# STM32L010x4 register map
File version: 1.0
Registers are 32-bit, read-write, reset 0x0 unless marked. A register's access mark holds for its fields unless they carry their own. Offsets are from the block's base; [hi:lo] are bit positions; {n}, {i} and the like mark numbered series; 'fields as' and 'values as' point back to an identical list.

## DBGMCU — Debug MCU
Base 0x40015800
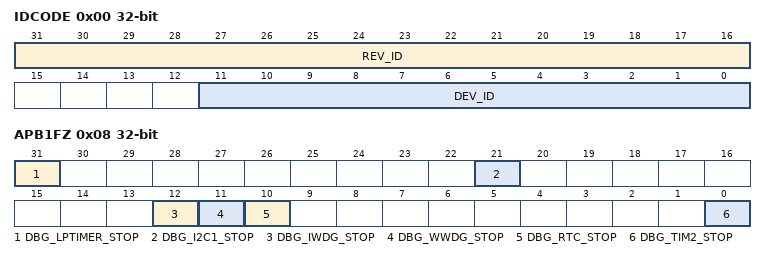
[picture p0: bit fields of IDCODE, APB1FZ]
0x00 IDCODE — MCU device ID code
  [31:16] REV_ID — REV_ID[15:0] bits (Revision Identifier)
  [11:0] DEV_ID — Device Identifier
0x04 CR — Debug MCU configuration register
  [2:0] DBG — Debug mode mask
0x08 APB1FZ — Debug MCU APB1 freeze register
  [31] DBG_LPTIMER_STOP — LPTIM1 counter stopped when core is halted
  [21] DBG_I2C1_STOP — I2C1 SMBUS timeout mode stopped when Core is halted
  [12] DBG_IWDG_STOP — Debug Independent Watchdog stopped when Core is halted
  [11] DBG_WWDG_STOP — Debug Window Watchdog stopped when Core is halted
  [10] DBG_RTC_STOP — RTC Calendar frozen when core is halted
  [0] DBG_TIM2_STOP — TIM2 counter stopped when core is halted
0x0C APB2FZ — Debug MCU APB2 freeze register
  [2] DBG_TIM21_STOP — TIM21 counter stopped when core is halted

## DMA1
Base 0x40020000
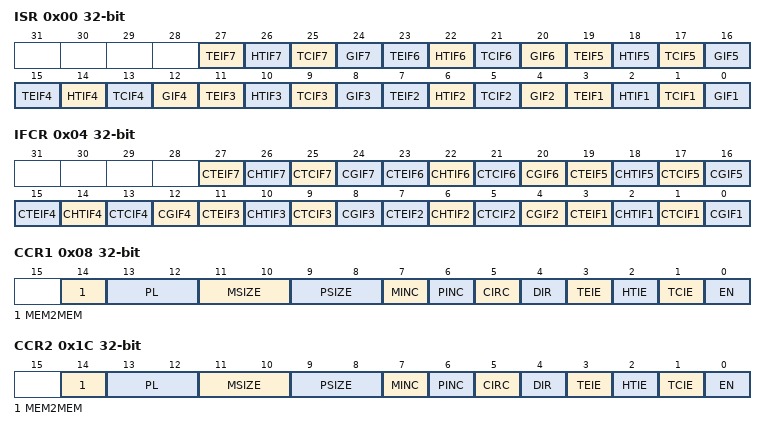
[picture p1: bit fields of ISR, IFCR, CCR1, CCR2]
0x00 ISR — DMA interrupt status register
  [4n-1] TEIF{n} (n=1..7) — Channel {n} Transfer Error flag
  [4n-2] HTIF{n} (n=1..7) — Channel {n} Half Transfer flag
  [4n-3] TCIF{n} (n=1..7) — Channel {n} Transfer Complete flag
  [4n-4] GIF{n} (n=1..7) — Channel {n} Global interrupt flag
0x04 IFCR — DMA interrupt flag clear register
  [4n-1] CTEIF{n} (n=1..7) — Channel {n} Transfer Error clear
  [4n-2] CHTIF{n} (n=1..7) — Channel {n} Half Transfer clear
  [4n-3] CTCIF{n} (n=1..7) — Channel {n} Transfer Complete clear
  [4n-4] CGIF{n} (n=1..7) — Channel {n} Global interrupt clear
0x08 CCR1 — DMA channel x configuration register
  [14] MEM2MEM — Memory to memory mode
  [13:12] PL — PL[1:0] bits(Channel Priority level)
  [11:10] MSIZE — MSIZE[1:0] bits (Memory size)
  [9:8] PSIZE — PSIZE[1:0] bits (Peripheral size)
  [7] MINC — Memory increment mode
  [6] PINC — Peripheral increment mode
  [5] CIRC — Circular mode
  [4] DIR — Data transfer direction
  [3] TEIE — Transfer error interrupt enable
  [2] HTIE — Half Transfer interrupt enable
  [1] TCIE — Transfer complete interrupt enable
  [0] EN — Channel enable
0x0C CNDTR1 — DMA channel x number of data register
  [15:0] NDT — Number of data to Transfer
0x10 CPAR1 — DMA channel x peripheral address register
  [31:0] PA — Peripheral Address
{0x0+0x14*i} CMAR{i} (i=1..5) — DMA channel x memory address register
  [31:0] MA — Memory Address
0x1C CCR2 — DMA channel x configuration register
  fields as CCR1
0x20 CNDTR2 — DMA channel x number of data register
  [15:0] NDT — Number of data to Transfer
0x24 CPAR2 — DMA channel x peripheral address register
  [31:0] PA — Peripheral Address
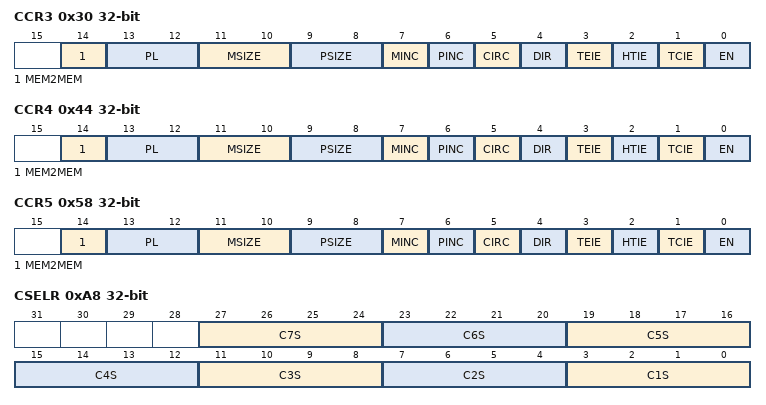
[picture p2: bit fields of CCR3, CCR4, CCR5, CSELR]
0x30 CCR3 — DMA channel x configuration register
  fields as CCR1
0x34 CNDTR3 — DMA channel x number of data register
  [15:0] NDT — Number of data to Transfer
0x38 CPAR3 — DMA channel x peripheral address register
  [31:0] PA — Peripheral Address
0x44 CCR4 — DMA channel x configuration register
  fields as CCR1
0x48 CNDTR4 — DMA channel x number of data register
  [15:0] NDT — Number of data to Transfer
0x4C CPAR4 — DMA channel x peripheral address register
  [31:0] PA — Peripheral Address
0x58 CCR5 — DMA channel x configuration register
  fields as CCR1
0x5C CNDTR5 — DMA channel x number of data register
  [15:0] NDT — Number of data to Transfer
0x60 CPAR5 — DMA channel x peripheral address register
  [31:0] PA — Peripheral Address
0xA8 CSELR — DMA channel selection register
  [4n-1:4n-4] C{n}S (n=1..7) — Channel {n} Selection

## FLASH — FLASH Registers
Base 0x40022000
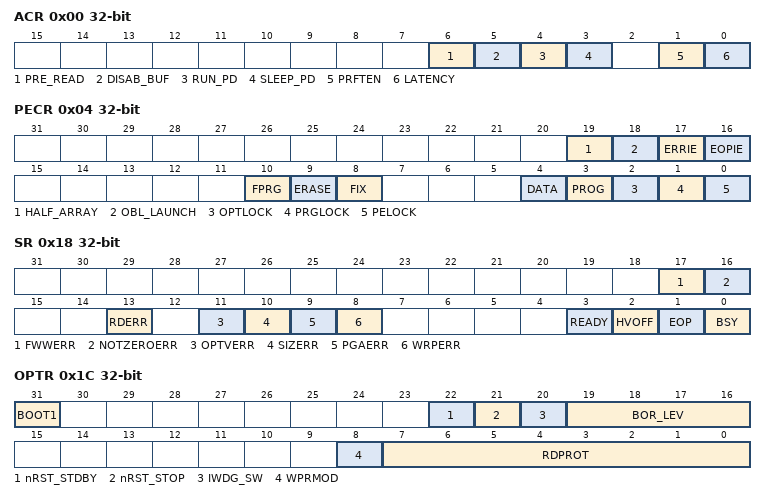
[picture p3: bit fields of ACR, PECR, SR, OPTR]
0x00 ACR — Access control register
  [6] PRE_READ — Pre-read data address
  [5] DISAB_BUF — Disable Buffer
  [4] RUN_PD — Flash mode during RUN mode
  [3] SLEEP_PD — Flash mode during sleep mode
  [1] PRFTEN — Prefetch Buffer Enable
  [0] LATENCY — LATENCY bit (Latency)
    0=FLASH Zero Latency cycle; 1=FLASH One Latency cycle
0x04 PECR — Program/erase control register
  [19] HALF_ARRAY — Half array mode
  [18] OBL_LAUNCH — Launch the option byte loading
  [17] ERRIE — Error interrupt
  [16] EOPIE — End of programming interrupt
  [10] FPRG — Fast Page/Half Page programming mode
  [9] ERASE — Page erasing mode
  [8] FIX — Fixed Time Data write for Word/Half Word/Byte programming
  [4] DATA — Data matrix selection
  [3] PROG — Program matrix selection
  [2] OPTLOCK — Option byte matrix Lock
  [1] PRGLOCK — Program matrix Lock
  [0] PELOCK — FLASH_PECR and Flash data Lock
0x08 PDKEYR — Power down key register
  [31:0] PDKEYR — FLASH_PEC and data matrix Key
0x0C PEKEYR — Program/erase key register
  [31:0] PEKEYR — FLASH_PEC and data matrix Key
0x10 PRGKEYR — Program memory key register
  [31:0] PRGKEYR — Program matrix Key
0x14 OPTKEYR — Option byte key register
  [31:0] OPTKEYR — Option bytes matrix Key
0x18 SR — Status register
  [17] FWWERR — Write/Errase operation aborted
  [16] NOTZEROERR — Not Zero error
  [13] RDERR — Read protected error
  [11] OPTVERR — Option Valid error
  [10] SIZERR — Size error
  [9] PGAERR — Programming Alignment Error
  [8] WRPERR — Write protection error
  [3] READY — Flash ready after low power mode
  [2] HVOFF — End of high voltage
  [1] EOP — End Of Programming
  [0] BSY — Busy
0x1C OPTR — Option byte register
  [31] BOOT1
  [22] nRST_STDBY
  [21] nRST_STOP
  [20] IWDG_SW
  [19:16] BOR_LEV — BOR_LEV[3:0] Brown Out Reset Threshold Level
  [8] WPRMOD — Selection of protection mode of WPR bits
  [7:0] RDPROT — Read Protection
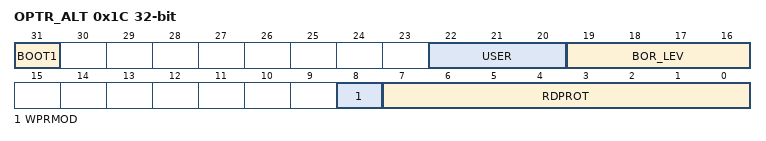
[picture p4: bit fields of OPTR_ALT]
0x1C OPTR_ALT (alternate view of OPTR) — Option byte register
  [31] BOOT1
  [22:20] USER — User Option Bytes
  [19:16] BOR_LEV — BOR_LEV[3:0] Brown Out Reset Threshold Level
  [8] WPRMOD — Selection of protection mode of WPR bits
  [7:0] RDPROT — Read Protection
0x20 WRPR — Write protection register
  [15:0] WRP — Write Protection bits

## CRC — CRC calculation unit
Base 0x40023000
0x00 DR — CRC Data register
  [31:0] DR — Data register bits
0x04 IDR 8-bit — CRC Independent data register
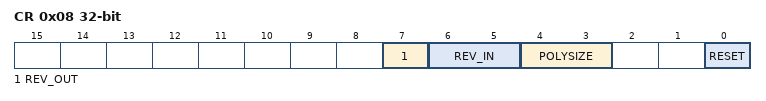
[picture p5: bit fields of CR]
0x08 CR — CRC Control register
  [7] REV_OUT — REV_OUT Reverse Output Data bits
    0=NONE (Output Data bit order not affected); 1=BIT (Output Data bit reversal done by bit)
  [6:5] REV_IN — REV_IN Reverse Input Data bits
    0=NONE (Input Data bit order not affected); 1=BYTE (Input Data bit reversal done by byte); 2=HALFWORD (Input Data bit reversal done by half-word); 3=WORD (Input Data bit reversal done by word)
  [4:3] POLYSIZE — Polynomial size bits
    0=POLYLENGTH_32B (32 bits Polynomial size); 1=POLYLENGTH_16B (16 bits Polynomial size); 2=POLYLENGTH_8B (8 bits Polynomial size); 3=POLYLENGTH_7B (7 bits Polynomial size)
  [0] RESET — RESET the CRC computation unit bit
0x10 INIT — Initial CRC value register
  [31:0] INIT — Initial CRC value bits
0x14 POL — CRC polynomial register
  [31:0] POL — Coefficients of the polynomial

## GPIOA — General Purpose IO
Base 0x50000000
Same registers: GPIOB 0x50000400, GPIOC 0x50000800
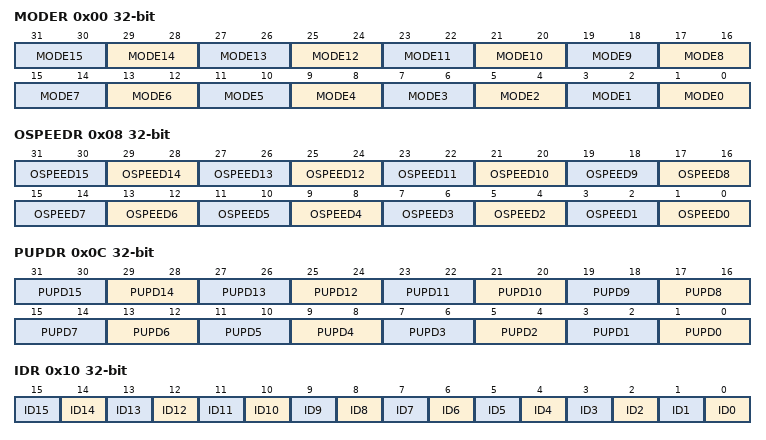
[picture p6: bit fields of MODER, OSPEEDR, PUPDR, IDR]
0x00 MODER — GPIO port mode register
  [2n+1:2n] MODE{n} (n=0..15)
0x04 OTYPER — GPIO port output type register
0x08 OSPEEDR — GPIO port output speed register
  [2n+1:2n] OSPEED{n} (n=0..15)
0x0C PUPDR — GPIO port pull-up/pull-down register
  [2n+1:2n] PUPD{n} (n=0..15)
0x10 IDR — GPIO port input data register
  [n] ID{n} (n=0..15)
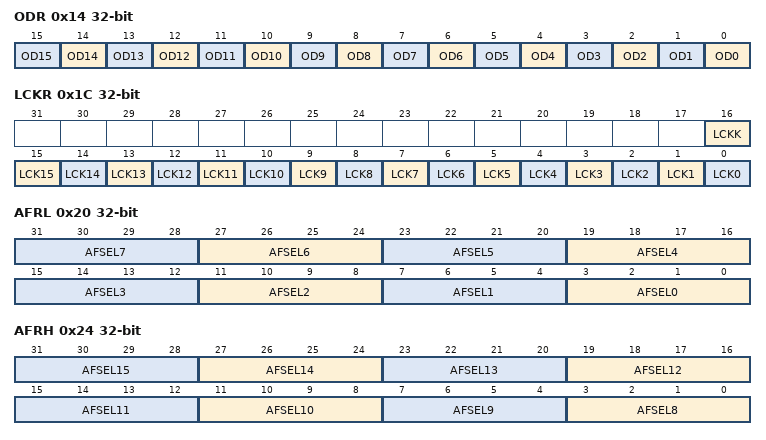
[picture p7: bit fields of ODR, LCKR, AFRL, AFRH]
0x14 ODR — GPIO port output data register
  [n] OD{n} (n=0..15)
0x18 BSRR — GPIO port bit set/reset registerBSRR
0x1C LCKR — GPIO port configuration lock register
  [16] LCKK, [n] LCK{n} (n=0..15)
0x20 AFRL — GPIO alternate function register
  [4n+3:4n] AFSEL{n} (n=0..7)
0x24 AFRH — GPIO alternate function register
  [4n-29:4n-32] AFSEL{n} (n=8..15)
0x28 BRR — GPIO bit reset register
